AUTOSAR XML (schema 4-1-1)
standard types defined: uint8, uint16, uint32, UInt8, UInt16, UInt32
package /BaseTypes
  ecuc value collection VCU
package /VCU/Types
  impl type Array8: category=ARRAY
    element Array8_elementsImpl: array-size=8, array-size-semantics=FIXED-SIZE, implementation-data-type=UInt8
  impl type Array2: category=ARRAY
    element Array2_elementsImpl: array-size=2, array-size-semantics=FIXED-SIZE, implementation-data-type=UInt8
package /VCU/Extract
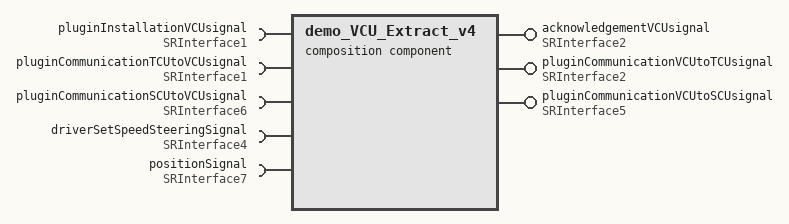
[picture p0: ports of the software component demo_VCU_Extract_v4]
  composition sw component type demo_VCU_Extract_v4
    require port pluginInstallationVCUsignal: required-interface=SRInterface1
    provide port acknowledgementVCUsignal: provided-interface=SRInterface2
    require port pluginCommunicationTCUtoVCUsignal: required-interface=SRInterface1
    provide port pluginCommunicationVCUtoTCUsignal: provided-interface=SRInterface2
    require port pluginCommunicationSCUtoVCUsignal: required-interface=SRInterface6
    provide port pluginCommunicationVCUtoSCUsignal: provided-interface=SRInterface5
    require port driverSetSpeedSteeringSignal: required-interface=SRInterface4
    require port positionSignal: required-interface=SRInterface7
    8 x component:
      PirteSWCProto: type=PirteSWC
      MotorSWCProto: type=MotorSWC
      ServoSWCProto: type=ServoSWC
      AdcSWCProto: type=AdcSWC
      FrontWheelSWCProto: type=FrontWheelSWC
      RearWheelSWCProto: type=RearWheelSWC
      LedSWCProto: type=LedSWC
      IoHwAbProto: type=IoHwAb
    connect PirteSWCProto.PirteSwcWriteDataToMotorSwcPort3 -> MotorSWCProto.MotorSwcReadDataFromPirteSwcPort1
    connect PirteSWCProto.PirteSwcWriteDataToServoSwcPort4 -> ServoSWCProto.ServoSwcReadDataFromPirteSwcPort1
    connect AdcSWCProto.AdcSwcWriteDataToPirteSwcPort1 -> PirteSWCProto.PirteSwcReadDataFromAdcSwcPort5
    connect FrontWheelSWCProto.FrontWheelSwcWriteDataToPirteSwcPort1 -> PirteSWCProto.PirteSwcReadDataFromFrontWheelSwcPort6
    connect RearWheelSWCProto.RearWheelSwcWriteDataToPirteSwcPort1 -> PirteSWCProto.PirteSwcReadDataFromRearWheelSwcPort7
    connect IoHwAbProto.IoHwReadAdcDataPort1 -> AdcSWCProto.AdcSwcReadDataFromAdcDriverPort2
    connect IoHwAbProto.IoHwReadFrontWheelDataPort2 -> FrontWheelSWCProto.FrontWheelSwcReadDataFromWheelSensorPort2
    connect IoHwAbProto.IoHwReadRearWheelDataPort3 -> RearWheelSWCProto.RearWheelSwcReadDataFromWheelSensorPort2
    connect PirteSWCProto.PirteSwcWriteLedPort13 -> LedSWCProto.LedSwcReadDataFromPirteSwcPort1
    connect IoHwAbProto.IoHwWriteLedDataPort4 -> LedSWCProto.LedSwcWriteDataToIoHwLedPort2
    connect IoHwAbProto.IoHwWriteSpeedDutyCyclePort5 -> MotorSWCProto.MotorSwcWriteDataToIoHwPwmPort3
    connect IoHwAbProto.IoHwWriteServoDutyCyclePort6 -> ServoSWCProto.ServoSwcWriteDataToIoHwPwmPort3
    connect PirteSWCProto.PirteSwcWriteSelectSpeedDataToMotorSwcPort15 -> MotorSWCProto.MotorSwcReadSelectDataFromPirteSwcPort4
    connect PirteSWCProto.PirteSwcWriteSelectSteerDataToServoSwcPort16 -> ServoSWCProto.ServoSwcReadSelectDataFromPirteSwcPort4
    delegate PirteSWCProto.PirteSwcReadInstallationDataFromTCUPort1 <-> outer port pluginInstallationVCUsignal
    delegate PirteSWCProto.PirteSwcWriteAcknowledgementDataToTCUPort2 <-> outer port acknowledgementVCUsignal
    delegate PirteSWCProto.PirteSwcReadCommunicationDataFromTCUPort10 <-> outer port pluginCommunicationTCUtoVCUsignal
    delegate PirteSWCProto.PirteSwcWriteCommunicationDataToTCUPort11 <-> outer port pluginCommunicationVCUtoTCUsignal
    delegate PirteSWCProto.PirteSwcReadDataFromSCUPort8 <-> outer port pluginCommunicationSCUtoVCUsignal
    delegate PirteSWCProto.PirteSwcWriteDataToSCUPort9 <-> outer port pluginCommunicationVCUtoSCUsignal
    delegate MotorSWCProto.MotorSwcReadDataFromTCUPort2 <-> outer port driverSetSpeedSteeringSignal
    delegate PirteSWCProto.PirteSwcReadPositionDataFromTCUPort12 <-> outer port positionSignal
  system demo_VCU_Extract_v4EcuExtract: category=ECU_EXTRACT
    system mapping ImplementationMappings
      sw-impl-mappings:
        8 x swc to impl mapping:
          PirteSWCProtoMapping: component-implementation=PirteSwcImplementation, component=demo_VCU_Extract_v4Prototype.PirteSWCProto
          MotorSWCProtoMapping: component-implementation=MotorSwcImplementation, component=demo_VCU_Extract_v4Prototype.MotorSWCProto
          ServoSWCProtoMapping: component-implementation=ServoSwcImplementation, component=demo_VCU_Extract_v4Prototype.ServoSWCProto
          AdcSWCProtoMapping: component-implementation=AdcSwcImplementation, component=demo_VCU_Extract_v4Prototype.AdcSWCProto
          FrontWheelSWCProtoMapping: component-implementation=FrontWheelSwcImplementation, component=demo_VCU_Extract_v4Prototype.FrontWheelSWCProto
          RearWheelSWCProtoMapping: component-implementation=RearWheelSwcImplementation, component=demo_VCU_Extract_v4Prototype.RearWheelSWCProto
          LedSWCProtoMapping: component-implementation=LedSwcImplementation, component=demo_VCU_Extract_v4Prototype.LedSWCProto
          IoHwAbProtoMapping: component-implementation=IoHwAbImplementation, component=demo_VCU_Extract_v4Prototype.IoHwAbProto
    system mapping SignalMappings
      data-mappings:
        data-element=demo_VCU_Extract_v4Prototype.pluginInstallationVCUsignal.argInt32, system-signal=pluginInstallationVCUsignalargInt32SSig
        data-element=demo_VCU_Extract_v4Prototype.acknowledgementVCUsignal.acknowledgementVCU, system-signal=acknowledgementVCUsignalacknowledgementVCUSSig
        data-element=demo_VCU_Extract_v4Prototype.pluginCommunicationTCUtoVCUsignal.argInt32, system-signal=pluginCommunicationTCUtoVCUsignalargInt32SSig
        data-element=demo_VCU_Extract_v4Prototype.pluginCommunicationVCUtoTCUsignal.acknowledgementVCU, system-signal=pluginCommunicationVCUtoTCUsignalacknowledgementVCUSSig
        data-element=demo_VCU_Extract_v4Prototype.pluginCommunicationSCUtoVCUsignal.argInt32, system-signal=pluginCommunicationSCUtoVCUsignalargInt32SSig
        data-element=demo_VCU_Extract_v4Prototype.pluginCommunicationVCUtoSCUsignal.argInt32, system-signal=pluginCommunicationVCUtoSCUsignalargInt32SSig
        data-element=demo_VCU_Extract_v4Prototype.driverSetSpeedSteeringSignal.dataInt32, system-signal=driverSetSpeedSteeringSignaldataInt32SSig
        data-element=demo_VCU_Extract_v4Prototype.driverSetSpeedSteeringSignal.dataInt32, system-signal=driverSetSpeedSteeringSignaldataInt32SSig
        data-element=demo_VCU_Extract_v4Prototype.positionSignal.argInt32, system-signal=positionSignalargInt32SSig
    root-software-compositions:
      root sw composition prototype demo_VCU_Extract_v4Prototype: software-composition=demo_VCU_Extract_v4
package /VCU/Extract/Communication
  pdu pluginInstallationVCUsignalargInt32IPdu
    signal pluginInstallationVCUsignalargInt32ISig: system signal pluginInstallationVCUsignalargInt32SSig
  pdu acknowledgementVCUsignalacknowledgementVCUIPdu
    signal acknowledgementVCUsignalacknowledgementVCUISig: system signal acknowledgementVCUsignalacknowledgementVCUSSig
  pdu pluginCommunicationTCUtoVCUsignalargInt32IPdu
    signal pluginCommunicationTCUtoVCUsignalargInt32ISig: system signal pluginCommunicationTCUtoVCUsignalargInt32SSig
  pdu pluginCommunicationVCUtoTCUsignalacknowledgementVCUIPdu
    signal pluginCommunicationVCUtoTCUsignalacknowledgementVCUISig: system signal pluginCommunicationVCUtoTCUsignalacknowledgementVCUSSig
  pdu pluginCommunicationSCUtoVCUsignalargInt32IPdu
    signal pluginCommunicationSCUtoVCUsignalargInt32ISig: system signal pluginCommunicationSCUtoVCUsignalargInt32SSig
  pdu pluginCommunicationVCUtoSCUsignalargInt32IPdu
    signal pluginCommunicationVCUtoSCUsignalargInt32ISig: system signal pluginCommunicationVCUtoSCUsignalargInt32SSig
  pdu driverSetSpeedSteeringSignaldataInt32IPdu
    signal driverSetSpeedSteeringSignaldataInt32ISig: system signal driverSetSpeedSteeringSignaldataInt32SSig
  pdu positionSignalargInt32IPdu
    signal positionSignalargInt32ISig: system signal positionSignalargInt32SSig
package /VCU/Interfaces
  4 x sender receiver interface:
    SRInterface1
      data argInt32: type=UInt32
      data pluginInstallationVCU: type=Array8
      data pluginCommunicationTCUtoVCU: type=Array8
    SRInterface2
      data acknowledgementVCU: type=UInt8
      data pluginCommunicationVCUtoTCU: type=Array8
    SRInterface3
      data dataInt32: type=UInt32
    SRInterface4
      data SpeedSteer: type=Array2
      data dataInt32: type=UInt32
  client server interface SetData: is-service=true
    operation Write: possible-error=[SetData/E_OK, SetData/E_NOT_OK]
      arg DutyCycle: type=UInt8, direction=OUT
    error E_OK: error-code=0
    error E_NOT_OK: error-code=1
  client server interface GetData: is-service=true
    operation Read: possible-error=[GetData/E_OK, GetData/E_NOT_OK]
      arg Data: type=UInt32, direction=IN
    error E_OK: error-code=0
    error E_NOT_OK: error-code=1
  client server interface SetPin: is-service=true
    operation PinOpt: possible-error=[SetPin/E_OK, SetPin/E_NOT_OK]
      arg Pin: type=UInt32, direction=OUT
      arg Level: type=UInt8, direction=OUT
    error E_OK: error-code=0
    error E_NOT_OK: error-code=1
  4 x sender receiver interface:
    SRInterface5
      data argInt32: type=UInt32
      data pluginCommunicationVCUtoSCU: type=Array8
    SRInterface6
      data argInt32: type=UInt32
      data pluginCommunicationSCUtoVCU: type=Array8
    SRInterface7
      data argInt32: type=UInt32
      data PositionData: type=Array8
    SRInterface8
      data SpeedSteer: type=Array2
package /VCU/Components
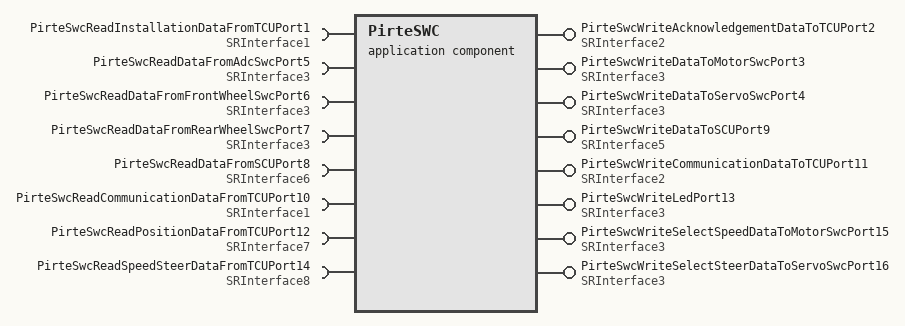
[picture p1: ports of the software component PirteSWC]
  application sw component type PirteSWC
    require port PirteSwcReadInstallationDataFromTCUPort1: required-interface=SRInterface1
    provide port PirteSwcWriteAcknowledgementDataToTCUPort2: provided-interface=SRInterface2
    provide port PirteSwcWriteDataToMotorSwcPort3: provided-interface=SRInterface3
    provide port PirteSwcWriteDataToServoSwcPort4: provided-interface=SRInterface3
    4 x require port:
      PirteSwcReadDataFromAdcSwcPort5: required-interface=SRInterface3
      PirteSwcReadDataFromFrontWheelSwcPort6: required-interface=SRInterface3
      PirteSwcReadDataFromRearWheelSwcPort7: required-interface=SRInterface3
      PirteSwcReadDataFromSCUPort8: required-interface=SRInterface6
    provide port PirteSwcWriteDataToSCUPort9: provided-interface=SRInterface5
    require port PirteSwcReadCommunicationDataFromTCUPort10: required-interface=SRInterface1
    provide port PirteSwcWriteCommunicationDataToTCUPort11: provided-interface=SRInterface2
    require port PirteSwcReadPositionDataFromTCUPort12: required-interface=SRInterface7
    provide port PirteSwcWriteLedPort13: provided-interface=SRInterface3
    require port PirteSwcReadSpeedSteerDataFromTCUPort14: required-interface=SRInterface8
    provide port PirteSwcWriteSelectSpeedDataToMotorSwcPort15: provided-interface=SRInterface3
    provide port PirteSwcWriteSelectSteerDataToServoSwcPort16: provided-interface=SRInterface3
    behavior PirteSwcBehavior: handle-termination-and-restart=NO-SUPPORT
      7 x data received event:
        PirteReadDataFromTCUEvent: start-on-event=Pirte_ReadInstallationDataFromTCU_Runnable, data=PirteSwcReadInstallationDataFromTCUPort1.pluginInstallationVCU
        AdcEvent: start-on-event=Pirte_ReadDataFromAdc_Runnable, data=PirteSwcReadDataFromAdcSwcPort5.dataInt32
        FrontWheelEvent: start-on-event=Pirte_ReadDataFromFrontWheel_Runnable, data=PirteSwcReadDataFromFrontWheelSwcPort6.dataInt32
        RearWheelEvent: start-on-event=Pirte_ReadDataFromRearWheel_Runnable, data=PirteSwcReadDataFromRearWheelSwcPort7.dataInt32
        PirteReadDataFromSCUEvent: start-on-event=Pirte_ReadDataFromSCU_Runnable, data=PirteSwcReadDataFromSCUPort8.pluginCommunicationSCUtoVCU
        PirteReadPositionDataEvent: start-on-event=Pirte_ReadPositionData_Runnable, data=PirteSwcReadPositionDataFromTCUPort12.PositionData
        PirteReadSpeedSteerEvent: start-on-event=Pirte_ReadSpeedSteerData_Runnable, data=PirteSwcReadSpeedSteerDataFromTCUPort14.SpeedSteer
      14 x runnable, all with minimum-start-interval=1.0:
        Pirte_ReadInstallationDataFromTCU_Runnable
          data-read-access:
            access dataReadAccess_Pirte_ReadInstallationDataFromTCU_Runnable_PirteSwcReadInstallationDataFromTCUPort1_pluginInstallationVCU: accessed-variable=PirteSwcReadInstallationDataFromTCUPort1.pluginInstallationVCU
            access dataReadAccess_Pirte_ReadInstallationDataFromTCU_Runnable_PirteSwcReadInstallationDataFromTCUPort1_argInt32: accessed-variable=PirteSwcReadInstallationDataFromTCUPort1.argInt32
        Pirte_WriteAcknowledgementDataToTCU_Runnable
          data-write-access:
            access PirteWriteDataToTCUack: accessed-variable=PirteSwcWriteAcknowledgementDataToTCUPort2.acknowledgementVCU
        Pirte_ReadCommunicationDataFromTCU_Runnable
          data-read-access:
            access dataReadAccess_Pirte_ReadCommunicationDataFromTCU_Runnable_PirteSwcReadCommunicationDataFromTCUPort10_pluginCommunicationTCUtoVCU: accessed-variable=PirteSwcReadCommunicationDataFromTCUPort10.pluginCommunicationTCUtoVCU
            access dataReadAccess_Pirte_ReadCommunicationDataFromTCU_Runnable_PirteSwcReadCommunicationDataFromTCUPort10_argInt32: accessed-variable=PirteSwcReadCommunicationDataFromTCUPort10.argInt32
        Pirte_WriteCommunicationDataFromTCU_Runnable
          data-write-access:
            access PirteWriteDataToTCU: accessed-variable=PirteSwcWriteCommunicationDataToTCUPort11.acknowledgementVCU
            access PirteWriteDataToTCU: accessed-variable=PirteSwcWriteCommunicationDataToTCUPort11.pluginCommunicationVCUtoTCU
        Pirte_WriteDataToMotor_Runnable
          data-write-access:
            access PirteWriteToMotor: accessed-variable=PirteSwcWriteDataToMotorSwcPort3.dataInt32
            access PirteWriteSelectSpeed: accessed-variable=PirteSwcWriteSelectSpeedDataToMotorSwcPort15.dataInt32
        Pirte_WriteDataToServo_Runnable
          data-write-access:
            access PirteWriteToServo: accessed-variable=PirteSwcWriteDataToServoSwcPort4.dataInt32
            access PirteWriteSelectSteering: accessed-variable=PirteSwcWriteSelectSteerDataToServoSwcPort16.dataInt32
        Pirte_ReadDataFromAdc_Runnable
          data-read-access:
            access dataReadAccess_Pirte_ReadDataFromAdc_Runnable_PirteSwcReadDataFromAdcSwcPort5_dataInt32: accessed-variable=PirteSwcReadDataFromAdcSwcPort5.dataInt32
        Pirte_ReadDataFromFrontWheel_Runnable
          data-read-access:
            access dataReadAccess_Pirte_ReadDataFromFrontWheel_Runnable_PirteSwcReadDataFromFrontWheelSwcPort6_dataInt32: accessed-variable=PirteSwcReadDataFromFrontWheelSwcPort6.dataInt32
        Pirte_ReadDataFromRearWheel_Runnable
          data-read-access:
            access dataReadAccess_Pirte_ReadDataFromRearWheel_Runnable_PirteSwcReadDataFromRearWheelSwcPort7_dataInt32: accessed-variable=PirteSwcReadDataFromRearWheelSwcPort7.dataInt32
        Pirte_ReadDataFromSCU_Runnable
          data-read-access:
            access dataReadAccess_Pirte_ReadDataFromSCU_Runnable_PirteSwcReadDataFromSCUPort8_pluginCommunicationSCUtoVCU: accessed-variable=PirteSwcReadDataFromSCUPort8.pluginCommunicationSCUtoVCU
            access dataReadAccess_Pirte_ReadDataFromSCU_Runnable_PirteSwcReadDataFromSCUPort8_argInt32: accessed-variable=PirteSwcReadDataFromSCUPort8.argInt32
        Pirte_WriteDataToSCU_Runnable
          data-write-access:
            access PirteWriteDataToSCU: accessed-variable=PirteSwcWriteDataToSCUPort9.pluginCommunicationVCUtoSCU
            access PirteWriteDataToSCU: accessed-variable=PirteSwcWriteDataToSCUPort9.argInt32
        Pirte_ReadPositionData_Runnable
          data-read-access:
            access dataReadAccess_Pirte_ReadPositionData_Runnable_PirteSwcReadPositionDataFromTCUPort12_PositionData: accessed-variable=PirteSwcReadPositionDataFromTCUPort12.PositionData
            access dataReadAccess_Pirte_ReadPositionData_Runnable_PirteSwcReadPositionDataFromTCUPort12_argInt32: accessed-variable=PirteSwcReadPositionDataFromTCUPort12.argInt32
        Pirte_WriteLedData_Runnable
          data-write-access:
            access PirteWriteDataToLed: accessed-variable=PirteSwcWriteLedPort13.dataInt32
        Pirte_ReadSpeedSteerData_Runnable
          data-read-access:
            access dataReadAccess_Pirte_ReadSpeedSteerData_Runnable_PirteSwcReadSpeedSteerDataFromTCUPort14_SpeedSteer: accessed-variable=PirteSwcReadSpeedSteerDataFromTCUPort14.SpeedSteer
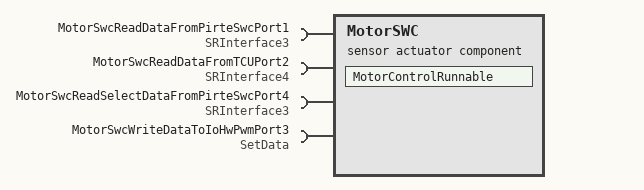
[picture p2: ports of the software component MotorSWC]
  sensor actuator sw component type MotorSWC
    4 x require port:
      MotorSwcReadDataFromPirteSwcPort1: required-interface=SRInterface3
      MotorSwcReadDataFromTCUPort2: required-interface=SRInterface4
      MotorSwcReadSelectDataFromPirteSwcPort4: required-interface=SRInterface3
      MotorSwcWriteDataToIoHwPwmPort3: required-interface=SetData
    behavior MotorSWCBehavior: handle-termination-and-restart=NO-SUPPORT
      data received event MotorReadDataFromPirteEvent: start-on-event=MotorControlRunnable, data=MotorSwcReadDataFromPirteSwcPort1.dataInt32
      data received event MotorReadDataFromTCUEvent: start-on-event=MotorControlRunnable, data=MotorSwcReadDataFromTCUPort2.SpeedSteer
      data received event SpeedSelectEvent: start-on-event=MotorControlRunnable, data=MotorSwcReadSelectDataFromPirteSwcPort4.dataInt32
      runnable MotorControlRunnable: minimum-start-interval=1.0
        data-read-access:
          4 x access:
            dataReadAccess_MotorControlRunnable_MotorSwcReadDataFromPirteSwcPort1_dataInt32: accessed-variable=MotorSwcReadDataFromPirteSwcPort1.dataInt32
            dataReadAccess_MotorControlRunnable_MotorSwcReadDataFromTCUPort2_SpeedSteer: accessed-variable=MotorSwcReadDataFromTCUPort2.SpeedSteer
            dataReadAccess_MotorControlRunnable_MotorSwcReadDataFromTCUPort2_dataInt32: accessed-variable=MotorSwcReadDataFromTCUPort2.dataInt32
            dataReadAccess_MotorControlRunnable_MotorSwcReadSelectDataFromPirteSwcPort4_dataInt32: accessed-variable=MotorSwcReadSelectDataFromPirteSwcPort4.dataInt32
        sync call MotorSwcWriteDataToIoHwPwmPort3_Write: operation=MotorSwcWriteDataToIoHwPwmPort3.Write, timeout=0.0
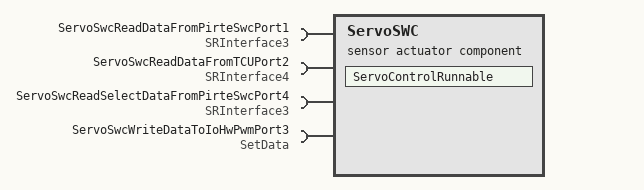
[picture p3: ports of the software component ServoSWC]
  sensor actuator sw component type ServoSWC
    4 x require port:
      ServoSwcReadDataFromPirteSwcPort1: required-interface=SRInterface3
      ServoSwcReadDataFromTCUPort2: required-interface=SRInterface4
      ServoSwcReadSelectDataFromPirteSwcPort4: required-interface=SRInterface3
      ServoSwcWriteDataToIoHwPwmPort3: required-interface=SetData
    behavior ServoSWCBehavior: handle-termination-and-restart=NO-SUPPORT
      data received event SteerReadDataFromPirteEvent: start-on-event=ServoControlRunnable, data=ServoSwcReadDataFromPirteSwcPort1.dataInt32
      data received event ServoReadDataFromTCUEvent: start-on-event=ServoControlRunnable, data=ServoSwcReadDataFromTCUPort2.SpeedSteer
      data received event SteerSelectEvent: start-on-event=ServoControlRunnable, data=ServoSwcReadSelectDataFromPirteSwcPort4.dataInt32
      runnable ServoControlRunnable: minimum-start-interval=1.0
        data-read-access:
          4 x access:
            dataReadAccess_ServoControlRunnable_ServoSwcReadDataFromPirteSwcPort1_dataInt32: accessed-variable=ServoSwcReadDataFromPirteSwcPort1.dataInt32
            dataReadAccess_ServoControlRunnable_ServoSwcReadDataFromTCUPort2_SpeedSteer: accessed-variable=ServoSwcReadDataFromTCUPort2.SpeedSteer
            dataReadAccess_ServoControlRunnable_ServoSwcReadDataFromTCUPort2_dataInt32: accessed-variable=ServoSwcReadDataFromTCUPort2.dataInt32
            dataReadAccess_ServoControlRunnable_ServoSwcReadSelectDataFromPirteSwcPort4_dataInt32: accessed-variable=ServoSwcReadSelectDataFromPirteSwcPort4.dataInt32
        sync call ServoSwcWriteDataToIoHwPwmPort3_Write: operation=ServoSwcWriteDataToIoHwPwmPort3.Write, timeout=0.0
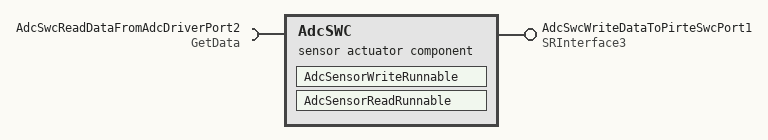
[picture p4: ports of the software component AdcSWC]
  sensor actuator sw component type AdcSWC
    provide port AdcSwcWriteDataToPirteSwcPort1: provided-interface=SRInterface3
    require port AdcSwcReadDataFromAdcDriverPort2: required-interface=GetData
    behavior AdcSWCBehavior: handle-termination-and-restart=NO-SUPPORT
      runnable AdcSensorWriteRunnable: minimum-start-interval=1.0
        data-write-access:
          access dataWriteAccess_AdcSensorWriteRunnable_AdcSwcWriteDataToPirteSwcPort1_dataInt32: accessed-variable=AdcSwcWriteDataToPirteSwcPort1.dataInt32
      runnable AdcSensorReadRunnable: minimum-start-interval=1.0, can-be-invoked-concurrently=true
        sync call AdcSwcReadDataFromAdcDriverPort2_Read: operation=AdcSwcReadDataFromAdcDriverPort2.Read, timeout=0.0
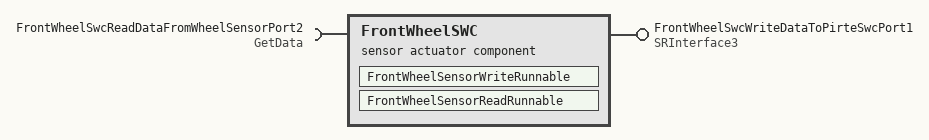
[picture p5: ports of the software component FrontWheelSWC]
  sensor actuator sw component type FrontWheelSWC
    provide port FrontWheelSwcWriteDataToPirteSwcPort1: provided-interface=SRInterface3
    require port FrontWheelSwcReadDataFromWheelSensorPort2: required-interface=GetData
    behavior FrontWheelSWCBehavior: handle-termination-and-restart=NO-SUPPORT
      runnable FrontWheelSensorWriteRunnable: minimum-start-interval=1.0
        data-write-access:
          access FrontWheelWriteDataToPirte: accessed-variable=FrontWheelSwcWriteDataToPirteSwcPort1.dataInt32
      runnable FrontWheelSensorReadRunnable: minimum-start-interval=1.0
        sync call FrontWheelSwcReadDataFromWheelSensorPort2_Read: operation=FrontWheelSwcReadDataFromWheelSensorPort2.Read, timeout=0.0
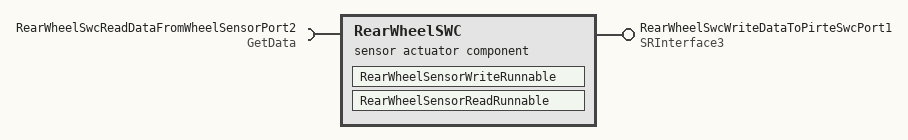
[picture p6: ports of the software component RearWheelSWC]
  sensor actuator sw component type RearWheelSWC
    provide port RearWheelSwcWriteDataToPirteSwcPort1: provided-interface=SRInterface3
    require port RearWheelSwcReadDataFromWheelSensorPort2: required-interface=GetData
    behavior RearWheelSWCBehavior: handle-termination-and-restart=NO-SUPPORT
      runnable RearWheelSensorWriteRunnable: minimum-start-interval=1.0
        data-write-access:
          access RearWheelWriteDataToPirte: accessed-variable=RearWheelSwcWriteDataToPirteSwcPort1.dataInt32
      runnable RearWheelSensorReadRunnable: minimum-start-interval=1.0
        sync call RearWheelSwcReadDataFromWheelSensorPort2_Read: operation=RearWheelSwcReadDataFromWheelSensorPort2.Read, timeout=0.0
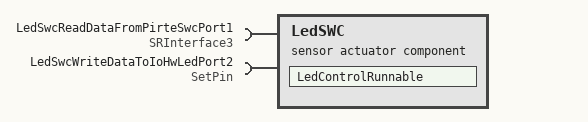
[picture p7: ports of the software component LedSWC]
  sensor actuator sw component type LedSWC
    require port LedSwcReadDataFromPirteSwcPort1: required-interface=SRInterface3
    require port LedSwcWriteDataToIoHwLedPort2: required-interface=SetPin
    behavior LedSWCbehavior: handle-termination-and-restart=NO-SUPPORT
      data received event LedReadDataFromPirteEvent: start-on-event=LedControlRunnable, data=LedSwcReadDataFromPirteSwcPort1.dataInt32
      runnable LedControlRunnable: minimum-start-interval=1.0
        data-read-access:
          access dataReadAccess_LedControlRunnable_LedSwcReadDataFromPirteSwcPort1_dataInt32: accessed-variable=LedSwcReadDataFromPirteSwcPort1.dataInt32
        sync call LedSwcWriteDataToIoHwLedPort2_PinOpt: operation=LedSwcWriteDataToIoHwLedPort2.PinOpt, timeout=0.0
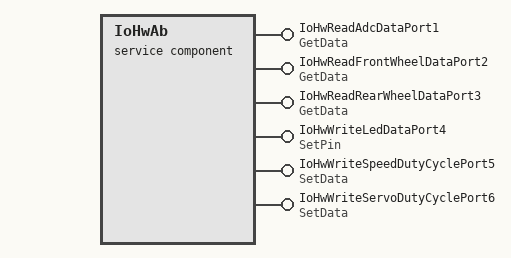
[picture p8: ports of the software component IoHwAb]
  service sw component type IoHwAb
    6 x provide port:
      IoHwReadAdcDataPort1: provided-interface=GetData
      IoHwReadFrontWheelDataPort2: provided-interface=GetData
      IoHwReadRearWheelDataPort3: provided-interface=GetData
      IoHwWriteLedDataPort4: provided-interface=SetPin
      IoHwWriteSpeedDutyCyclePort5: provided-interface=SetData
      IoHwWriteServoDutyCyclePort6: provided-interface=SetData
    behavior IoHwAbBehavior: handle-termination-and-restart=NO-SUPPORT
      6 x operation invoked event:
        IoHwReadAdcDataPort1_Read: start-on-event=IoHw_Read_AdcSensor, operation=IoHwReadAdcDataPort1.Read
        IoHwReadFrontWheelDataPort2_Read: start-on-event=IoHw_Read_FrontWheelSensor, operation=IoHwReadFrontWheelDataPort2.Read
        IoHwReadRearWheelDataPort3_Read: start-on-event=IoHw_Read_RearWheelSensor, operation=IoHwReadRearWheelDataPort3.Read
        IoHwWriteLedDataPort4_PinOpt: start-on-event=IoHw_Write_Led, operation=IoHwWriteLedDataPort4.PinOpt
        IoHwWriteSpeedDutyCyclePort5_Write: start-on-event=IoHw_WriteSpeed_DutyCycle, operation=IoHwWriteSpeedDutyCyclePort5.Write
        IoHwWriteServoDutyCyclePort6_Write: start-on-event=IoHw_WriteServo_DutyCycle, operation=IoHwWriteServoDutyCyclePort6.Write
      port-api-options:
        {port-defined-argument-value{value=UInt32:0, value-type=UInt32}, port=IoHwReadAdcDataPort1}
        {port-defined-argument-value{value=UInt32:0, value-type=UInt32}, port=IoHwReadFrontWheelDataPort2}
        {port-arg-values=[{value=UInt32:0, value-type=UInt32}, {value=UInt8:0, value-type=UInt8}], port=IoHwWriteLedDataPort4}
        {port-defined-argument-value{value=UInt8:0, value-type=UInt8}, port=IoHwWriteSpeedDutyCyclePort5}
        {port-defined-argument-value{value=UInt8:0, value-type=UInt8}, port=IoHwWriteServoDutyCyclePort6}
      6 x runnable, all with minimum-start-interval=1.0, can-be-invoked-concurrently=true:
        IoHw_Read_AdcSensor
        IoHw_Read_FrontWheelSensor
        IoHw_Read_RearWheelSensor
        IoHw_Write_Led
        IoHw_WriteSpeed_DutyCycle
        IoHw_WriteServo_DutyCycle
  8 x swc implementation, all with programming-language=C, vendor-id=0:
    PirteSwcImplementation: behavior=PirteSwcBehavior
      code-descriptors:
        code src: artifact-descriptors=autosar-engineering-object={short-label=artifactDescriptor, category=artifactDescriptorCategory}
      resource consumption resourceConsumption
    MotorSwcImplementation: behavior=MotorSWCBehavior
      code-descriptors:
        code src: artifact-descriptors=autosar-engineering-object={short-label=artifactDescriptor, category=artifactDescriptorCategory}
      resource consumption resourceConsumption
    ServoSwcImplementation: behavior=ServoSWCBehavior
      code-descriptors:
        code src: artifact-descriptors=autosar-engineering-object={short-label=artifactDescriptor, category=artifactDescriptorCategory}
      resource consumption resourceConsumption
    AdcSwcImplementation: behavior=AdcSWCBehavior
      code-descriptors:
        code src: artifact-descriptors=autosar-engineering-object={short-label=artifactDescriptor, category=artifactDescriptorCategory}
      resource consumption resourceConsumption
    FrontWheelSwcImplementation: behavior=FrontWheelSWCBehavior
      code-descriptors:
        code src: artifact-descriptors=autosar-engineering-object={short-label=artifactDescriptor, category=artifactDescriptorCategory}
      resource consumption resourceConsumption
    RearWheelSwcImplementation: behavior=RearWheelSWCBehavior
      code-descriptors:
        code src: artifact-descriptors=autosar-engineering-object={short-label=artifactDescriptor, category=artifactDescriptorCategory}
      resource consumption resourceConsumption
    LedSwcImplementation: behavior=LedSWCbehavior
      code-descriptors:
        code src: artifact-descriptors=autosar-engineering-object={short-label=artifactDescriptor, category=artifactDescriptorCategory}
      resource consumption resourceConsumption
    IoHwAbImplementation: behavior=IoHwAbBehavior
      code-descriptors:
        code src: artifact-descriptors=autosar-engineering-object={short-label=artifactDescriptor, category=artifactDescriptorCategory}
      resource consumption resourceConsumption
